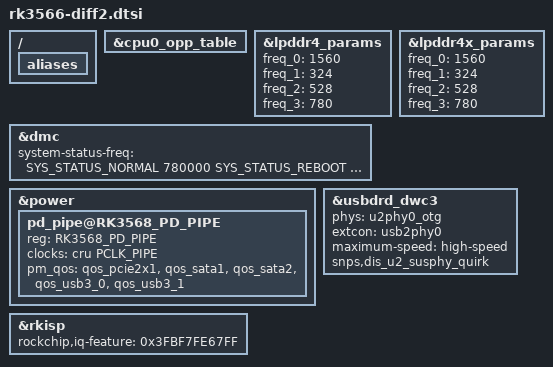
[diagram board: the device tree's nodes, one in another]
// SPDX-License-Identifier: (GPL-2.0+ OR MIT)
/*
 * Copyright (c) 2020 Rockchip Electronics Co., Ltd.
 */

/*
 * fork from arch/arm64/boot/dts/rockchip/rk3566.dtsi
 */

#include "rk3568.dtsi"

/ {
	aliases {
		/delete-property/ ethernet0;
	};
};

&cpu0_opp_table {
	/delete-node/ opp-1992000000;
};

&lpddr4_params {
	/* freq info, freq_0 is final frequency, unit: MHz */
	freq_0 = <1560>;
	freq_1 = <324>;
	freq_2 = <528>;
	freq_3 = <780>;
};

&lpddr4x_params {
	/* freq info, freq_0 is final frequency, unit: MHz */
	freq_0 = <1560>;
	freq_1 = <324>;
	freq_2 = <528>;
	freq_3 = <780>;
};


&dmc {
	system-status-freq = <
		/*system status         freq(KHz)*/
		SYS_STATUS_NORMAL       780000
		SYS_STATUS_REBOOT       1560000
		SYS_STATUS_SUSPEND      324000
		SYS_STATUS_VIDEO_1080P  528000
		SYS_STATUS_BOOST        1560000
		SYS_STATUS_ISP          1560000
		SYS_STATUS_PERFORMANCE  1560000
	>;
};

&power {
	pd_pipe@RK3568_PD_PIPE {
		reg = <RK3568_PD_PIPE>;
		clocks = <&cru PCLK_PIPE>;
		pm_qos = <&qos_pcie2x1>,
			 <&qos_sata1>,
			 <&qos_sata2>,
			 <&qos_usb3_0>,
			 <&qos_usb3_1>;
	};
};

&rkisp {
	rockchip,iq-feature = /bits/ 64 <0x3FBF7FE67FF>;
};

&usbdrd_dwc3 {
	phys = <&u2phy0_otg>;
	phy-names = "usb2-phy";
	extcon = <&usb2phy0>;
	maximum-speed = "high-speed";
	snps,dis_u2_susphy_quirk;
};

/delete-node/ &combphy0_us;
/delete-node/ &gmac0_clkin;
/delete-node/ &gmac0_xpcsclk;
/delete-node/ &gmac0;
/delete-node/ &pcie30_phy_grf;
/delete-node/ &pcie30phy;
/delete-node/ &pcie3x1;
/delete-node/ &pcie3x2;
/delete-node/ &qos_pcie3x1;
/delete-node/ &qos_pcie3x2;
/delete-node/ &qos_sata0;
/delete-node/ &sata0;
